# TLE987x register map
Vendor: Infineon; Series: MOTIX MCU; File version: 4.2
TLE987x Family
CPU: CM3 r0p0, little endian, no MPU, no FPU, 4 interrupt priority bits
Registers are 32-bit, read-write, reset 0x0 unless marked. A register's access mark holds for its fields unless they carry their own. Offsets are from the block's base; lines under a group give offsets from that group; [hi:lo] are bit positions; {n}, {i} and the like mark numbered series; 'fields as' and 'values as' point back to an identical list; <NAME> marks a mode.

## Memory map
0x40004000 ADC1 size 0x4000 — ADC1 Module
0x4000C000 CCU6 size 0x4000 — Capture Compare Unit 6
0x40010000 GPT12E size 0x4000 — General Purpose Timer 12E
0x40034000 BDRV size 0x4000 — Bridge Driver
0x48004000 TIMER2 size 0x1000 — TIMER2 Module
0x48005000 TIMER21 size 0x1000 — TIMER21 Module
0x48006000 TIMER3 size 0x21 — TIMER3 Module
0x48018000 MF size 0x4000 — Measurement Function
0x4801C000 ADC2 size 0x2000 — ADC2 Module
0x4801E000 LIN size 0x8 — Local Interconnect Network
0x48020000 UART1 size 0x2000 — UART1 Module
0x48022000 UART2 size 0x2000 — UART2 Module
0x48024000 SSC1 size 0x2000 — SSC1 Module
0x48026000 SSC2 size 0x2000 — SSC2 Module
0x48028000 PORT size 0x2000 — GPIO PORTs
0x50004000 PMU size 0x1000 — Power Management Unit
0x50005000 SCU size 0x1000 — System Control Unit
0x50006000 SCUPM size 0x1000 — System Control Unit for Power Modules
0x50014000 DMA size 0x4000 — Direct Memeory Access
0xE000E000 CPU size 0x1000 — CPU Core

## Interrupts
0 GPT1_Int (GPT12E) — Interrupt node 0: GPT1 Block
1 GPT2_Int (GPT12E) — Interrupt node 1: GPT2 Block
2 ADC2_Tmr3_Int (ADC2) — Interrupt node 2: ADC2, Timer3, BEMF
3 ADC1_VREF5_Int (ADC1) — Interrupt node 3: ADC1, VAREF
4 CCU6_SR0_Int (CCU6) — Interrupt node 4: CCU6 node0
5 CCU6_SR1_Int (CCU6) — Interrupt node 5: CCU6 node1
6 CCU6_SR2_Int (CCU6) — Interrupt node 6: CCU6 node2
7 CCU6_SR3_Int (CCU6) — Interrupt node 7: CCU6 node3
8 SSC1_Int (SSC1) — Interrupt node 8: SSC1
9 SSC2_Int (SSC2) — Interrupt node 9: SSC2
10 UART1_LIN_Tmr2_Int (UART1) — Interrupt node10: UART1(ASC,LIN), Timer2
11 UART2_Tmr21_EINT2_Int (UART2) — Interrupt node11: UART2, Timer21, EINT2
12 EXINT0_MON_Int (SCU) — Interrupt node12: EINT0, MON
13 EXINT1_Int (SCU) — Interrupt node13: EINT1
14 BDRV_CP_Int (BDRV) — Interrupt node14: BDRV, Charge Pump
15 DMA_Int (DMA) — Interrupt node15: DMA

## LIN — Local Interconnect Network
Base 0x4801E000
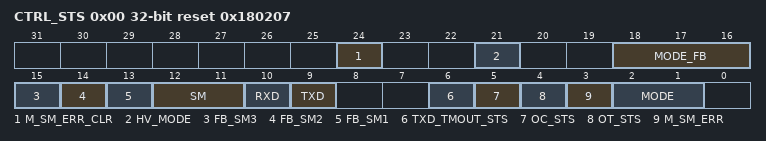
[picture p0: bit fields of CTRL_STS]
0x00 CTRL_STS access per field reset 0x180207 (reset mask 0xFFF81BFF) — LIN Transceiver Control and Status
  [24] M_SM_ERR_CLR rw — LIN Transceiver Mode or Slope Mode Error Clear
    0=no_action (Status unchanged); 1=Clear (Status clear)
  [21] HV_MODE rw — LIN Transceiver High Voltage Input - Output Mode
    0=DISABLE (High Voltage Mode Entry is disabled); 1=ENABLE (High Voltage Mode Entry is enabled)
  [18:16] MODE_FB ro — Feedback Signals for LIN Transmitter Mode Settings
  [15] FB_SM3 ro — Feedback Signal 3 for Slope Mode Setting
  [14] FB_SM2 ro — Feedback Signal 2 for Slope Mode Setting
  [13] FB_SM1 ro — Feedback Signal 1 for Slope Mode Setting
  [12:11] SM rw — LIN Transmitter Slope mode control
    0=Normal_Slope_Mode (for max. 20 kBaud); 1=Fast_Slope_Mode (for max. 40 kBaud); 2=Low_Slope_Mode (for max. 10.4 kBaud); 3=Flash_Mode (for max. 150 kBaud)
  [10] RXD ro — Output Signal of Receiver
  [9] TXD rw — LIN Transmitter switch on (only used when LIN_HV_MODE is set)
    0=Pull_Down_LIN_Line (Transmitter is switched on); 1=Pull_Up_Resistor_is_active (Transmitter is switched off)
  [6] TXD_TMOUT_STS ro — LIN TXD time-out status
    0=NO_TIMEOUT (no time-out occured); 1=TIMEOUT (time-out occured)
  [5] OC_STS ro — LIN Receiver Overcurrent Status
    0=no_Overcurrent (overcurrent status occured); 1=overcurrent status occured
  [4] OT_STS ro — LIN Receiver Overtemperature Status
    0=no_Overtemperature (overtemperature occured); 1=overtemperature occured
  [3] M_SM_ERR ro — LIN Transceiver Mode or Slope Mode Error
    0=no_Mode_or_Slope_Mode_Error (Status (see corresponding Feedback registers)); 1=Mode_or_Slope_Mode_Error (Status (see corresponding Feedback registers))
  [2:1] MODE rw — LIN transceiver power mode control
    0=LIN_Sleep_Mode (LIN module switched to LIN Sleep Mode); 1=LIN_Receive_Only_Mode (LIN module switched to LIN Receive Only Mode); 3=LIN_Normal_Mode (LIN module switched to LIN Normal Mode)
